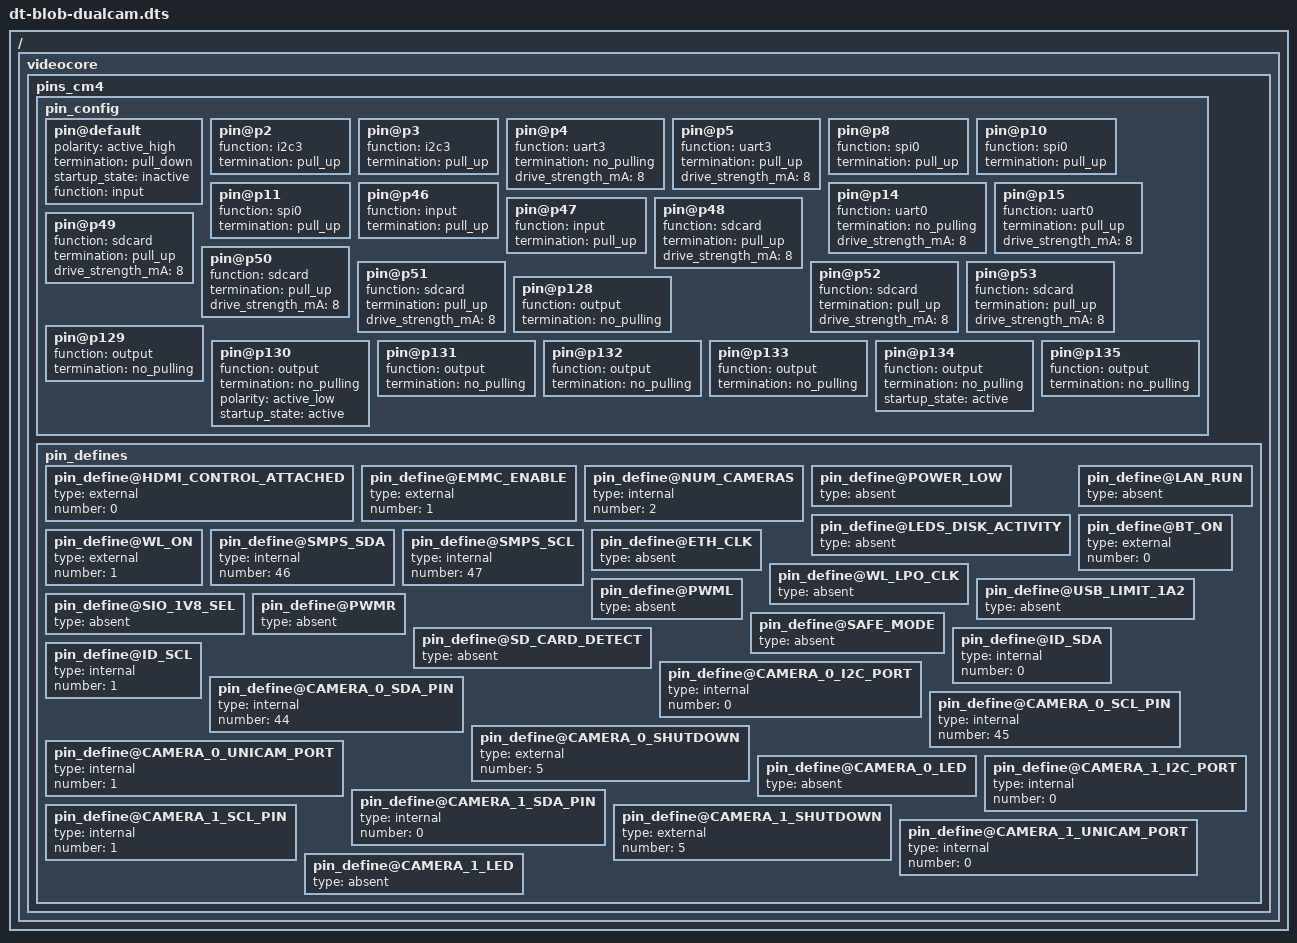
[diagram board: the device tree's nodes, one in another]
/dts-v1/;

/ {
   videocore {

      pins_cm4 { // Pi 4 CM4
         pin_config {
            pin@default {
               polarity = "active_high";
               termination = "pull_down";
               startup_state = "inactive";
               function = "input";
            }; // pin
            pin@p2  { function = "i2c3";   termination = "pull_up"; }; // I2C 3 SDA
            pin@p3  { function = "i2c3";   termination = "pull_up"; }; // I2C 3 SCL
            pin@p4 { function = "uart3";  termination = "no_pulling"; drive_strength_mA = < 8 >; }; // TX uart3
            pin@p5 { function = "uart3";  termination = "pull_up"; drive_strength_mA = < 8 >; }; // RX uart3
            pin@p8  { function = "spi0";   termination = "pull_up"; }; // SPI0 CS0
            pin@p10  { function = "spi0";   termination = "pull_up"; }; // SPI0 MOSI
            pin@p11  { function = "spi0";   termination = "pull_up"; }; // SPI0 SCK
            pin@p14 { function = "uart0";  termination = "no_pulling"; drive_strength_mA = < 8 >; }; // TX uart0
            pin@p15 { function = "uart0";  termination = "pull_up"; drive_strength_mA = < 8 >; }; // RX uart0
            pin@p46 { function = "input";   termination = "pull_up";    }; // SMPS_SCL
            pin@p47 { function = "input";   termination = "pull_up";    }; // SMPS_SDA
            pin@p48 { function = "sdcard"; termination = "pull_up";    drive_strength_mA = < 8 >; }; // SD CLK
            pin@p49 { function = "sdcard"; termination = "pull_up";    drive_strength_mA = < 8 >; }; // SD CMD
            pin@p50 { function = "sdcard"; termination = "pull_up";    drive_strength_mA = < 8 >; }; // SD D0
            pin@p51 { function = "sdcard"; termination = "pull_up";    drive_strength_mA = < 8 >; }; // SD D1
            pin@p52 { function = "sdcard"; termination = "pull_up";    drive_strength_mA = < 8 >; }; // SD D2
            pin@p53 { function = "sdcard"; termination = "pull_up";    drive_strength_mA = < 8 >; }; // SD D3
            pin@p128 { function = "output"; termination = "no_pulling"; }; // BT_ON
            pin@p129 { function = "output"; termination = "no_pulling"; }; // WL_ON
            pin@p130 { function = "output"; termination = "no_pulling"; polarity = "active_low"; startup_state = "active"; }; // PWR_LED (RED)
            pin@p131 { function = "output"; termination = "no_pulling"; }; // ANT1
            pin@p132 { function = "output"; termination = "no_pulling"; }; // SD VDDIO
            pin@p133 { function = "output"; termination = "no_pulling"; }; // Camera shutdown
            pin@p134 { function = "output"; termination = "no_pulling"; startup_state = "active"; }; // SD_PWR_ON
            pin@p135 { function = "output"; termination = "no_pulling"; }; // ANT2
         }; // pin_config

         pin_defines {
            pin_define@HDMI_CONTROL_ATTACHED {
               type = "external";
               number = <0>;
            };
            pin_define@EMMC_ENABLE {
               type = "external";
               number = <1>;
            };
            pin_define@NUM_CAMERAS {
               type = "internal";
               number = <2>;
            };
            pin_define@POWER_LOW {
               type = "absent";
            };
            pin_define@LEDS_DISK_ACTIVITY {
               type = "absent";
            };
            pin_define@LAN_RUN {
               type = "absent";
            };
            pin_define@BT_ON {
               type = "external";
               number = <0>;
            };
            pin_define@WL_ON {
               type = "external";
               number = <1>;
            };
            pin_define@SMPS_SDA {
               type = "internal";
               number = <46>;
            };
            pin_define@SMPS_SCL {
               type = "internal";
               number = <47>;
            };
            pin_define@ETH_CLK {
               type = "absent";
            };
            pin_define@WL_LPO_CLK {
               type = "absent";
            };
            pin_define@USB_LIMIT_1A2 {
               type = "absent";
            };
            pin_define@SIO_1V8_SEL {
               type = "absent";
            };
            pin_define@PWML {
               type = "absent";
            };
            pin_define@PWMR {
               type = "absent";
            };
            pin_define@SAFE_MODE {
               type = "absent";
            };
            pin_define@SD_CARD_DETECT {
               type = "absent";
            };
            pin_define@ID_SDA {
               type = "internal";
               number = <0>;
            };
            pin_define@ID_SCL {
               type = "internal";
               number = <1>;
            };
            pin_define@CAMERA_0_I2C_PORT {
               type = "internal";
               number = <0>;
            };
            pin_define@CAMERA_0_SDA_PIN {
               type = "internal";
               number = <44>;
            };
            pin_define@CAMERA_0_SCL_PIN {
               type = "internal";
               number = <45>;
            };
            pin_define@CAMERA_0_SHUTDOWN {
               type = "external";
               number = <5>;
            };
            pin_define@CAMERA_0_UNICAM_PORT {
               type = "internal";
               number = <1>;
            };
            pin_define@CAMERA_0_LED {
               type = "absent";
            };
            pin_define@CAMERA_1_I2C_PORT {
               type = "internal";
               number = <0>;
            };
            pin_define@CAMERA_1_SDA_PIN {
               type = "internal";
               number = <0>;
            };
            pin_define@CAMERA_1_SCL_PIN {
               type = "internal";
               number = <1>;
            };
            pin_define@CAMERA_1_SHUTDOWN {
               type = "external";
               number = <5>;
            };
            pin_define@CAMERA_1_UNICAM_PORT {
               type = "internal";
               number = <0>;
            };
            pin_define@CAMERA_1_LED {
               type = "absent";
            };
         }; // pin_defines
      }; // pins

   };
};
